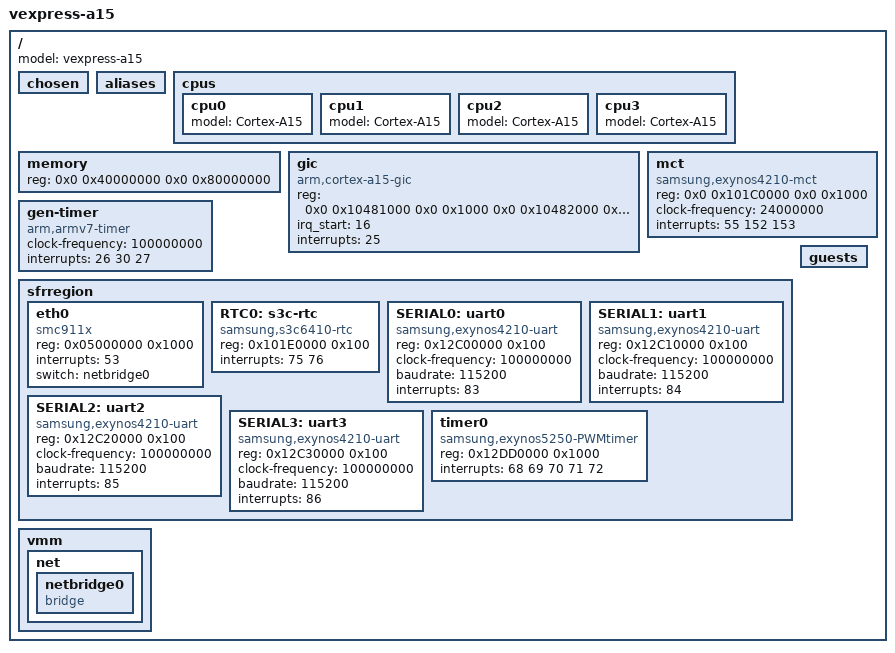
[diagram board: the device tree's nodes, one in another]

/ {
	#address-cells = <2>;
	#size-cells = <2>;
	model = "vexpress-a15";

	chosen { };
	aliases { };

	cpus {
		cpu0 {
			device_type = "cpu";
			model = "Cortex-A15";
		};

		cpu1 {
			device_type = "cpu";
			model = "Cortex-A15";
		};

		cpu2 {
			device_type = "cpu";
			model = "Cortex-A15";
		};

		cpu3 {
			device_type = "cpu";
			model = "Cortex-A15";
		};
	};

	memory {
		device_type = "memory"; 
		reg = <0x0 0x40000000 0x0 0x80000000>; /* 2 GB */
	};

	gic { /* Generic Interrupt Controller */
      		device_type = "pic";
      		compatible = "arm,cortex-a15-gic", "arm,cortex-a9-gic";
      		reg = <0x0 0x10481000 0x0 0x1000   /* Dist Interface */
		       0x0 0x10482000 0x0 0x1000   /* CPU Interface */
		       0x0 0x10484000 0x0 0x2000   /* VCPU Control Interface */
		       0x0 0x10486000 0x0 0x2000>; /* VCPU Interface */
		irq_start = <16>;
		interrupts = <25>; /* VGIC Maintanence IRQ */
	};
	
	mct {
        device_type = "timer";
        compatible = "samsung,exynos4210-mct";
        reg = <0x0 0x101C0000 0x0 0x1000>;
        clock-frequency = <24000000>;
        interrupts = <55 152 153>;
       };

	gen-timer { /* Generic Timer */
      		device_type = "timer";
      		compatible = "arm,armv7-timer";
		clock-frequency = <100000000>;
		interrupts = <26 30 27>;
	};

	sfrregion {
		#address-cells = <1>;
		#size-cells = <1>;

		eth0 {
			device_type = "nic";
			compatible = "smc911x";
			reg = <0x05000000 0x1000>;
			interrupts = <53>;
			switch = "netbridge0";
		};

		RTC0: s3c-rtc {
			device_type = "rtc";
			compatible = "samsung,s3c6410-rtc";
			reg = <0x101E0000 0x100>;
			interrupts = <75 76>;
		};

		SERIAL0: uart0 {
			device_type = "serial";
			compatible = "samsung,exynos4210-uart";
			reg = <0x12C00000 0x100>;
			clock-frequency = <100000000>;
			baudrate = <115200>;
			interrupts = <83>;
		};

		SERIAL1: uart1 {
			device_type = "serial";
			compatible = "samsung,exynos4210-uart";
			reg = <0x12C10000 0x100>;
			clock-frequency = <100000000>;
			baudrate = <115200>;
			interrupts = <84>;
		};

		SERIAL2: uart2 {
			device_type = "serial";
			compatible = "samsung,exynos4210-uart";
			reg = <0x12C20000 0x100>;
			clock-frequency = <100000000>;
			baudrate = <115200>;
			interrupts = <85>;
		};

		SERIAL3: uart3 {
			device_type = "serial";
			compatible = "samsung,exynos4210-uart";
			reg = <0x12C30000 0x100>;
			clock-frequency = <100000000>;
			baudrate = <115200>;
			interrupts = <86>;
		};

		timer0 {
			device_type = "timer";
			compatible = "samsung,exynos5250-PWMtimer";
			reg = <0x12DD0000 0x1000>;
			interrupts = <68 69 70 71 72>;
		};
	};

	vmm {
		net {
			netbridge0 {
				device_type = "netswitch";
				compatible = "bridge";
			};
		};
	};

	/* Empty guests node */
	guests {
	};
};

/* Add guest templates */
/include/ "../../../common/guests/realview-pb-a8.dtsi"
/include/ "../../../common/guests/vexpress-a9x2.dtsi"
/include/ "../../../common/guests/vexpress-a15x2.dtsi"

